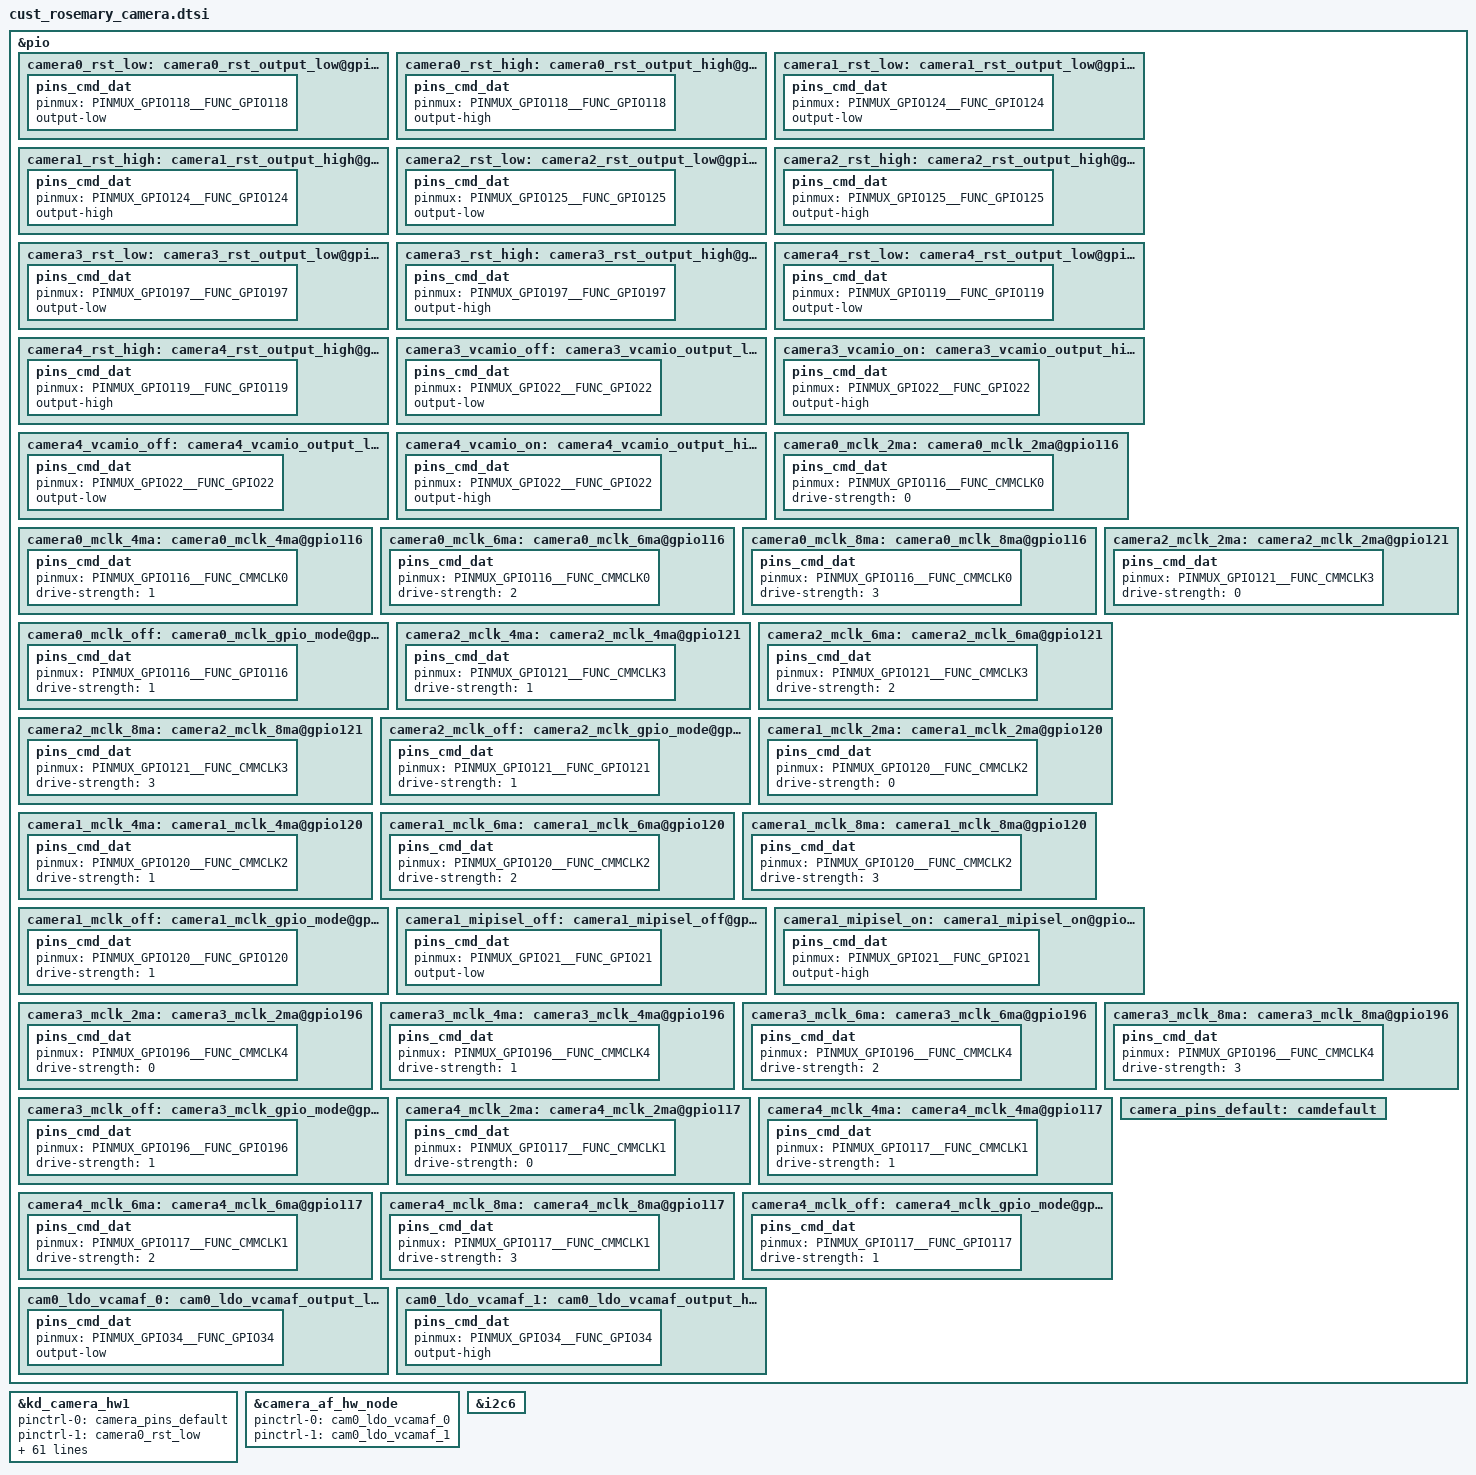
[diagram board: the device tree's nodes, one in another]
/*
 * Copyright (c) 2017 MediaTek Inc.
 * Copyright (C) 2021 XiaoMi, Inc.
 *
 * This program is free software; you can redistribute it and/or modify
 * it under the terms of the GNU General Public License version 2 as
 * published by the Free Software Foundation.
 *
 * This program is distributed in the hope that it will be useful,
 * but WITHOUT ANY WARRANTY; without even the implied warranty of
 * MERCHANTABILITY or FITNESS FOR A PARTICULAR PURPOSE.  See the
 * GNU General Public License for more details.
 */
/* CAMERA GPIO standardization */
&pio {
/*camera RST*/
	camera0_rst_low: camera0_rst_output_low@gpio118 {
		pins_cmd_dat {
			pinmux = <PINMUX_GPIO118__FUNC_GPIO118>;
			output-low;
		};
	};
	camera0_rst_high: camera0_rst_output_high@gpio118 {
		pins_cmd_dat {
			pinmux = <PINMUX_GPIO118__FUNC_GPIO118>;
			output-high;
		};
	};
	camera1_rst_low: camera1_rst_output_low@gpio124 {
		pins_cmd_dat {
			pinmux = <PINMUX_GPIO124__FUNC_GPIO124>;
			output-low;
		};
	};
	camera1_rst_high: camera1_rst_output_high@gpio124 {
		pins_cmd_dat {
			pinmux = <PINMUX_GPIO124__FUNC_GPIO124>;
			output-high;
		};
	};
	camera2_rst_low: camera2_rst_output_low@gpio125 {
		pins_cmd_dat {
			pinmux = <PINMUX_GPIO125__FUNC_GPIO125>;
			output-low;
		};
	};
	camera2_rst_high: camera2_rst_output_high@gpio125 {
		pins_cmd_dat {
			pinmux = <PINMUX_GPIO125__FUNC_GPIO125>;
			output-high;
		};
	};
       camera3_rst_low: camera3_rst_output_low@gpio197 {
                pins_cmd_dat {
                        pinmux = <PINMUX_GPIO197__FUNC_GPIO197>;
                        output-low;
                };
        };
       camera3_rst_high: camera3_rst_output_high@gpio197 {
                pins_cmd_dat {
                        pinmux = <PINMUX_GPIO197__FUNC_GPIO197>;
                        output-high;
                };
        };
	camera4_rst_low: camera4_rst_output_low@gpio119 {
		pins_cmd_dat {
			pinmux = <PINMUX_GPIO119__FUNC_GPIO119>;
			output-low;
		};
	};
	camera4_rst_high: camera4_rst_output_high@gpio119 {
		pins_cmd_dat {
			pinmux = <PINMUX_GPIO119__FUNC_GPIO119>;
			output-high;
		};
	};
/*camera AVDD DVDD DOVDD*/
       camera3_vcamio_off: camera3_vcamio_output_low@gpio22 {
               pins_cmd_dat {
                       pinmux = <PINMUX_GPIO22__FUNC_GPIO22>;
                       output-low;
               };
       };
       camera3_vcamio_on: camera3_vcamio_output_high@gpio22 {
               pins_cmd_dat {
                       pinmux = <PINMUX_GPIO22__FUNC_GPIO22>;
                       output-high;
               };
       };
	camera4_vcamio_off: camera4_vcamio_output_low@gpio22 {
		pins_cmd_dat {
			pinmux = <PINMUX_GPIO22__FUNC_GPIO22>;
			output-low;
		};
	};
	camera4_vcamio_on: camera4_vcamio_output_high@gpio22 {
		pins_cmd_dat {
			pinmux = <PINMUX_GPIO22__FUNC_GPIO22>;
			output-high;
		};
	};
/*camera MCLK*/
	camera0_mclk_2ma: camera0_mclk_2ma@gpio116 {
		pins_cmd_dat {
			pinmux = <PINMUX_GPIO116__FUNC_CMMCLK0>;
			drive-strength = <0>;
		};
	};
	camera0_mclk_4ma: camera0_mclk_4ma@gpio116 {
		pins_cmd_dat {
			pinmux = <PINMUX_GPIO116__FUNC_CMMCLK0>;
			drive-strength = <1>;
		};
	};
	camera0_mclk_6ma: camera0_mclk_6ma@gpio116 {
		pins_cmd_dat {
			pinmux = <PINMUX_GPIO116__FUNC_CMMCLK0>;
			drive-strength = <2>;
		};
	};
	camera0_mclk_8ma: camera0_mclk_8ma@gpio116 {
		pins_cmd_dat {
			pinmux = <PINMUX_GPIO116__FUNC_CMMCLK0>;
			drive-strength = <3>;
		};
	};
	camera0_mclk_off: camera0_mclk_gpio_mode@gpio116 {
		pins_cmd_dat {
			pinmux = <PINMUX_GPIO116__FUNC_GPIO116>;
			drive-strength = <1>;
		};
	};
	camera2_mclk_2ma: camera2_mclk_2ma@gpio121 {
		pins_cmd_dat {
			pinmux = <PINMUX_GPIO121__FUNC_CMMCLK3>;
			drive-strength = <0>;
		};
	};
	camera2_mclk_4ma: camera2_mclk_4ma@gpio121 {
		pins_cmd_dat {
			pinmux = <PINMUX_GPIO121__FUNC_CMMCLK3>;
			drive-strength = <1>;
		};
	};
	camera2_mclk_6ma: camera2_mclk_6ma@gpio121 {
		pins_cmd_dat {
			pinmux = <PINMUX_GPIO121__FUNC_CMMCLK3>;
			drive-strength = <2>;
		};
	};
	camera2_mclk_8ma: camera2_mclk_8ma@gpio121 {
		pins_cmd_dat {
			pinmux = <PINMUX_GPIO121__FUNC_CMMCLK3>;
			drive-strength = <3>;
		};
	};
	camera2_mclk_off: camera2_mclk_gpio_mode@gpio121 {
		pins_cmd_dat {
			pinmux = <PINMUX_GPIO121__FUNC_GPIO121>;
			drive-strength = <1>;
		};
	};
	camera1_mclk_2ma: camera1_mclk_2ma@gpio120 {
		pins_cmd_dat {
			pinmux = <PINMUX_GPIO120__FUNC_CMMCLK2>;
			drive-strength = <0>;
		};
	};
	camera1_mclk_4ma: camera1_mclk_4ma@gpio120 {
		pins_cmd_dat {
			pinmux = <PINMUX_GPIO120__FUNC_CMMCLK2>;
			drive-strength = <1>;
		};
	};
	camera1_mclk_6ma: camera1_mclk_6ma@gpio120 {
		pins_cmd_dat {
			pinmux = <PINMUX_GPIO120__FUNC_CMMCLK2>;
			drive-strength = <2>;
		};
	};
	camera1_mclk_8ma: camera1_mclk_8ma@gpio120 {
		pins_cmd_dat {
			pinmux = <PINMUX_GPIO120__FUNC_CMMCLK2>;
			drive-strength = <3>;
		};
	};
	camera1_mclk_off: camera1_mclk_gpio_mode@gpio120 {
		pins_cmd_dat {
			pinmux = <PINMUX_GPIO120__FUNC_GPIO120>;
			drive-strength = <1>;
		};
	};
	camera1_mipisel_off: camera1_mipisel_off@gpio21 {
		pins_cmd_dat {
			pinmux = <PINMUX_GPIO21__FUNC_GPIO21>;
			output-low;
		};
	};
	camera1_mipisel_on: camera1_mipisel_on@gpio21 {
		pins_cmd_dat {
			pinmux = <PINMUX_GPIO21__FUNC_GPIO21>;
			output-high;
		};
	};
       camera3_mclk_2ma: camera3_mclk_2ma@gpio196 {
               pins_cmd_dat {
                       pinmux = <PINMUX_GPIO196__FUNC_CMMCLK4>;
                        drive-strength = <0>;
                };
        };
       camera3_mclk_4ma: camera3_mclk_4ma@gpio196 {
                pins_cmd_dat {
                       pinmux = <PINMUX_GPIO196__FUNC_CMMCLK4>;
                        drive-strength = <1>;
                };
        };
       camera3_mclk_6ma: camera3_mclk_6ma@gpio196 {
                pins_cmd_dat {
                       pinmux = <PINMUX_GPIO196__FUNC_CMMCLK4>;
                        drive-strength = <2>;
                };
        };
       camera3_mclk_8ma: camera3_mclk_8ma@gpio196 {
                pins_cmd_dat {
                       pinmux = <PINMUX_GPIO196__FUNC_CMMCLK4>;
                        drive-strength = <3>;
                };
        };
       camera3_mclk_off: camera3_mclk_gpio_mode@gpio196 {
                pins_cmd_dat {
                      pinmux = <PINMUX_GPIO196__FUNC_GPIO196>;
                        drive-strength = <1>;
                };
        };
	camera4_mclk_2ma: camera4_mclk_2ma@gpio117 {
		pins_cmd_dat {
			pinmux = <PINMUX_GPIO117__FUNC_CMMCLK1>;
			drive-strength = <0>;
		};
	};
	camera4_mclk_4ma: camera4_mclk_4ma@gpio117 {
		pins_cmd_dat {
			pinmux = <PINMUX_GPIO117__FUNC_CMMCLK1>;
			drive-strength = <1>;
		};
	};
	camera4_mclk_6ma: camera4_mclk_6ma@gpio117 {
		pins_cmd_dat {
			pinmux = <PINMUX_GPIO117__FUNC_CMMCLK1>;
			drive-strength = <2>;
		};
	};
	camera4_mclk_8ma: camera4_mclk_8ma@gpio117 {
		pins_cmd_dat {
			pinmux = <PINMUX_GPIO117__FUNC_CMMCLK1>;
			drive-strength = <3>;
		};
	};
	camera4_mclk_off: camera4_mclk_gpio_mode@gpio117 {
		pins_cmd_dat {
			pinmux = <PINMUX_GPIO117__FUNC_GPIO117>;
			drive-strength = <1>;
		};
	};
	camera_pins_default: camdefault {
	};
};
&kd_camera_hw1 {
	pinctrl-names = "default",
			"cam0_rst0", "cam0_rst1",
			"cam1_rst0", "cam1_rst1",
			"cam2_rst0", "cam2_rst1",
                        "cam3_rst0", "cam3_rst1",
			"cam4_rst0", "cam4_rst1",
                        "cam3_ldo_vcamio_0", "cam3_ldo_vcamio_1",
			"cam4_ldo_vcamio_0", "cam4_ldo_vcamio_1",
			"cam0_mclk_off",
			"cam0_mclk_2mA", "cam0_mclk_4mA",
			"cam0_mclk_6mA", "cam0_mclk_8mA",
			"cam_mipi_switch_sel_0", "cam_mipi_switch_sel_1",
			"cam1_mclk_off",
			"cam1_mclk_2mA", "cam1_mclk_4mA",
			"cam1_mclk_6mA", "cam1_mclk_8mA",
			"cam2_mclk_off",
			"cam2_mclk_2mA", "cam2_mclk_4mA",
			"cam2_mclk_6mA", "cam2_mclk_8mA",
                        "cam3_mclk_off",
                        "cam3_mclk_2mA", "cam3_mclk_4mA",
                        "cam3_mclk_6mA", "cam3_mclk_8mA",
			"cam4_mclk_off",
			"cam4_mclk_2mA", "cam4_mclk_4mA",
			"cam4_mclk_6mA", "cam4_mclk_8mA";
	pinctrl-0 = <&camera_pins_default>;
	pinctrl-1 = <&camera0_rst_low>;
	pinctrl-2 = <&camera0_rst_high>;
	pinctrl-3 = <&camera1_rst_low>;
	pinctrl-4 = <&camera1_rst_high>;
	pinctrl-5 = <&camera2_rst_low>;
	pinctrl-6 = <&camera2_rst_high>;
        pinctrl-7  = <&camera3_rst_low>;
        pinctrl-8  = <&camera3_rst_high>;
        pinctrl-9  = <&camera4_rst_low>;
        pinctrl-10 = <&camera4_rst_high>;
        pinctrl-11 = <&camera3_vcamio_off>;
        pinctrl-12 = <&camera3_vcamio_on>;
        pinctrl-13 = <&camera4_vcamio_off>;
        pinctrl-14 = <&camera4_vcamio_on>;
	pinctrl-15 = <&camera0_mclk_off>;
	pinctrl-16 = <&camera0_mclk_2ma>;
	pinctrl-17 = <&camera0_mclk_4ma>;
	pinctrl-18 = <&camera0_mclk_6ma>;
	pinctrl-19 = <&camera0_mclk_8ma>;
	pinctrl-20 = <&camera1_mipisel_off>;
	pinctrl-21 = <&camera1_mipisel_on>;
	pinctrl-22 = <&camera1_mclk_off>;
	pinctrl-23 = <&camera1_mclk_2ma>;
	pinctrl-24 = <&camera1_mclk_4ma>;
	pinctrl-25 = <&camera1_mclk_6ma>;
	pinctrl-26 = <&camera1_mclk_8ma>;
	pinctrl-27 = <&camera2_mclk_off>;
	pinctrl-28 = <&camera2_mclk_2ma>;
	pinctrl-29 = <&camera2_mclk_4ma>;
	pinctrl-30 = <&camera2_mclk_6ma>;
	pinctrl-31 = <&camera2_mclk_8ma>;
        pinctrl-32 = <&camera3_mclk_off>;
        pinctrl-33 = <&camera3_mclk_2ma>;
        pinctrl-34 = <&camera3_mclk_4ma>;
        pinctrl-35 = <&camera3_mclk_6ma>;
        pinctrl-36 = <&camera3_mclk_8ma>;
        pinctrl-37 = <&camera4_mclk_off>;
        pinctrl-38 = <&camera4_mclk_2ma>;
        pinctrl-39 = <&camera4_mclk_4ma>;
        pinctrl-40 = <&camera4_mclk_6ma>;
        pinctrl-41 = <&camera4_mclk_8ma>;
	cam0_vcamd-supply = <&wl2866d_dvdd2>;
	cam0_vcama-supply = <&wl2866d_avdd2>;
	cam0_vcamio-supply = <&mt_pmic_vcamio_ldo_reg>;
	cam1_vcamio-supply = <&mt_pmic_vcamio_ldo_reg>;
	cam1_vcama-supply = <&wl2866d_avdd1>;
	cam1_vcamd-supply = <&wl2866d_dvdd1>;
	cam2_vcamio-supply = <&mt_pmic_vcamio_ldo_reg>;
	cam2_vcama-supply = <&wl2866d_avdd1>;
	cam2_vcamd-supply = <&wl2866d_dvdd1>;
        cam3_vcama-supply = <&wl2866d_avdd1>;
	cam4_vcama-supply = <&wl2866d_avdd1>;
	status = "okay";
};
/* CAMERA GPIO end */

&pio {
	cam0_ldo_vcamaf_0: cam0_ldo_vcamaf_output_low@gpio34 {
		pins_cmd_dat {
			pinmux = <PINMUX_GPIO34__FUNC_GPIO34>;
			output-low;
		};
	};
	cam0_ldo_vcamaf_1: cam0_ldo_vcamaf_output_high@gpio34 {
		pins_cmd_dat {
			pinmux = <PINMUX_GPIO34__FUNC_GPIO34>;
			output-high;
		};
	};
};

&camera_af_hw_node {
	pinctrl-names = "cam0_ldo_vcamaf_0", "cam0_ldo_vcamaf_1";
	pinctrl-0 = <&cam0_ldo_vcamaf_0>;
	pinctrl-1 = <&cam0_ldo_vcamaf_1>;
	status = "okay";
};

/* CAMERA specify sensor */
&kd_camera_hw1 {
	cam0_enable_sensor = "ov64b40semco_mipi_raw ov64b40ofilm_mipi_raw";
	cam1_enable_sensor = "ov13b10sunny_mipi_raw ov13b10ofilm_mipi_raw";
	cam2_enable_sensor = "imx355ofilm_mipi_raw imx355sunny_mipi_raw";
        cam3_enable_sensor = "ov02b1bofilm_mipi_raw gc02m1bsunny_mipi_mono";
        cam4_enable_sensor = "gc02m1ofilm_mipi_raw gc02m1sunny_mipi_raw";
};
/* CAMERA specify sensor end */

&i2c6 {
        #include "wl2866d.dtsi"
};
